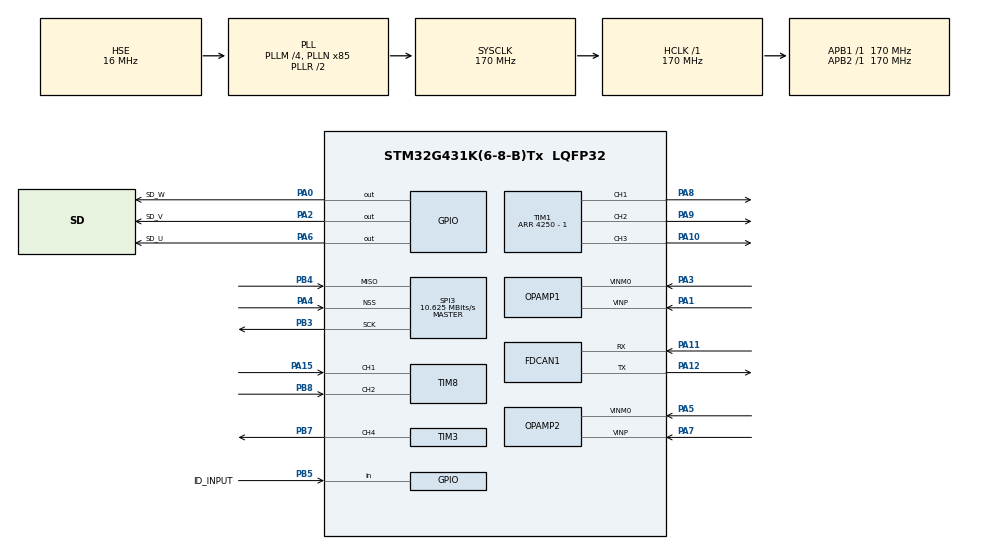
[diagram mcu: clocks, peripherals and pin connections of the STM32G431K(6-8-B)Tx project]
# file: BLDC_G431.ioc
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ADC1.Channel-0\#ChannelRegularConversion=ADC_CHANNEL_VOPAMP1
ADC1.DMAAccessModeView=ENABLE
ADC1.DMAContinuousRequests=ENABLE
ADC1.ExternalTrigConv=ADC_EXTERNALTRIG_T1_TRGO
ADC1.Mode=ADC_DUALMODE_REGSIMULT
ADC1.NbrOfConversion=1
ADC1.NbrOfConversionFlag=1
ADC1.SamplingTime-0\#ChannelRegularConversion=ADC_SAMPLETIME_12CYCLES_5
ADC1.TwoSamplingDelay=ADC_TWOSAMPLINGDELAY_1CYCLE
ADC1.master=1
ADC2.Channel-0\#ChannelRegularConversion=ADC_CHANNEL_VOPAMP2
ADC2.DMAAccessModeView=ENABLE
ADC2.Mode=ADC_DUALMODE_REGSIMULT
ADC2.NbrOfConversionFlag=1
ADC2.OffsetNumber-0\#ChannelRegularConversion=ADC_OFFSET_NONE
ADC2.Rank-0\#ChannelRegularConversion=1
ADC2.SamplingTime-0\#ChannelRegularConversion=ADC_SAMPLETIME_12CYCLES_5
Dma.ADC1.1.Direction=DMA_PERIPH_TO_MEMORY
Dma.ADC1.1.EventEnable=DISABLE
Dma.ADC1.1.Instance=DMA1_Channel1
Dma.ADC1.1.MemDataAlignment=DMA_MDATAALIGN_WORD
Dma.ADC1.1.MemInc=DMA_MINC_ENABLE
Dma.ADC1.1.Mode=DMA_CIRCULAR
Dma.ADC1.1.PeriphDataAlignment=DMA_PDATAALIGN_WORD
Dma.ADC1.1.PeriphInc=DMA_PINC_DISABLE
Dma.ADC1.1.Polarity=HAL_DMAMUX_REQ_GEN_RISING
Dma.ADC1.1.Priority=DMA_PRIORITY_VERY_HIGH
Dma.ADC1.1.RequestNumber=1
Dma.ADC1.1.SignalID=NONE
Dma.ADC1.1.SyncEnable=DISABLE
Dma.ADC1.1.SyncPolarity=HAL_DMAMUX_SYNC_NO_EVENT
Dma.ADC1.1.SyncRequestNumber=1
Dma.ADC1.1.SyncSignalID=NONE
Dma.Request0=TIM3_CH4
Dma.Request1=ADC1
Dma.TIM3_CH4.0.Direction=DMA_MEMORY_TO_PERIPH
Dma.TIM3_CH4.0.EventEnable=DISABLE
Dma.TIM3_CH4.0.Instance=DMA1_Channel2
Dma.TIM3_CH4.0.MemDataAlignment=DMA_MDATAALIGN_WORD
Dma.TIM3_CH4.0.MemInc=DMA_MINC_ENABLE
Dma.TIM3_CH4.0.Mode=DMA_CIRCULAR
Dma.TIM3_CH4.0.PeriphDataAlignment=DMA_PDATAALIGN_HALFWORD
Dma.TIM3_CH4.0.PeriphInc=DMA_PINC_DISABLE
Dma.TIM3_CH4.0.Polarity=HAL_DMAMUX_REQ_GEN_RISING
Dma.TIM3_CH4.0.Priority=DMA_PRIORITY_MEDIUM
Dma.TIM3_CH4.0.RequestNumber=1
Dma.TIM3_CH4.0.SignalID=NONE
Dma.TIM3_CH4.0.SyncEnable=DISABLE
Dma.TIM3_CH4.0.SyncPolarity=HAL_DMAMUX_SYNC_NO_EVENT
Dma.TIM3_CH4.0.SyncRequestNumber=1
Dma.TIM3_CH4.0.SyncSignalID=NONE
FDCAN1.AutoRetransmission=ENABLE
FDCAN1.CalculateBaudRateNominal=999999
FDCAN1.CalculateTimeBitNominal=1000
FDCAN1.CalculateTimeQuantumNominal=11.764705882352942
FDCAN1.DataPrescaler=5
FDCAN1.DataSyncJumpWidth=8
FDCAN1.DataTimeSeg1=8
FDCAN1.DataTimeSeg2=8
FDCAN1.FrameFormat=FDCAN_FRAME_FD_BRS
FDCAN1.NominalPrescaler=2
FDCAN1.NominalSyncJumpWidth=21
FDCAN1.NominalTimeSeg1=63
FDCAN1.NominalTimeSeg2=21
FDCAN1.StdFiltersNbr=1
Mcu.Family=STM32G4
Mcu.Name=STM32G431K(6-8-B)Tx
Mcu.Package=LQFP32
NVIC.ADC1_2_IRQn=true\:0\:0\:false\:false\:true\:true\:true\:true
NVIC.DMA1_Channel1_IRQn=true\:0\:0\:false\:false\:true\:false\:true\:true
NVIC.DMA1_Channel2_IRQn=true\:0\:0\:false\:false\:true\:false\:true\:true
NVIC.FDCAN1_IT0_IRQn=true\:0\:0\:false\:false\:true\:true\:true\:true
NVIC.PriorityGroup=NVIC_PRIORITYGROUP_4
NVIC.TIM1_UP_TIM16_IRQn=true\:0\:0\:false\:false\:true\:true\:true\:true
NVIC.TIM6_DAC_IRQn=true\:0\:0\:false\:false\:true\:true\:true\:true
NVIC.TIM8_UP_IRQn=true\:0\:0\:false\:false\:true\:true\:true\:true
OPAMP1.PgaGain=OPAMP_PGA_GAIN_32_OR_MINUS_31
OPAMP2.PgaGain=OPAMP_PGA_GAIN_32_OR_MINUS_31
PA0.GPIO_Label=SD_W
PA0.GPIO_PuPd=GPIO_PULLDOWN
PA0.Signal=GPIO_Output
PA1.Mode=PGA Internally connected_IO0_BIAS
PA1.Signal=OPAMP1_VINP
PA10.Signal=S_TIM1_CH3
PA11.Mode=FDCAN_Activate
PA11.Signal=FDCAN1_RX
PA12.Mode=FDCAN_Activate
PA12.Signal=FDCAN1_TX
PA13.Mode=Serial_Wire
PA13.Signal=SYS_JTMS-SWDIO
PA14.Mode=Serial_Wire
PA14.Signal=SYS_JTCK-SWCLK
PA15.Signal=S_TIM8_CH1
PA2.GPIO_Label=SD_V
PA2.GPIO_PuPd=GPIO_PULLDOWN
PA2.Signal=GPIO_Output
PA3.Mode=PGA Internally connected_IO0_BIAS
PA3.Signal=OPAMP1_VINM0
PA4.Mode=NSS_Signal_Hard_Input
PA4.Signal=SPI3_NSS
PA5.Mode=PGA Internally connected_IO0_BIAS
PA5.Signal=OPAMP2_VINM0
PA6.GPIO_Label=SD_U
PA6.GPIO_PuPd=GPIO_PULLDOWN
PA6.Signal=GPIO_Output
PA7.Mode=PGA Internally connected_IO0_BIAS
PA7.Signal=OPAMP2_VINP
PA8.Signal=S_TIM1_CH1
PA9.Signal=S_TIM1_CH2
PB3.Mode=RX_Only_Simplex_Unidirect_Master
PB3.Signal=SPI3_SCK
PB4.Mode=RX_Only_Simplex_Unidirect_Master
PB4.Signal=SPI3_MISO
PB5.GPIO_Label=ID_INPUT
PB5.Signal=GPIO_Input
PB7.GPIO_Speed=GPIO_SPEED_FREQ_HIGH
PB7.Signal=S_TIM3_CH4
PB8-BOOT0.Signal=S_TIM8_CH2
PF0-OSC_IN.Mode=HSE-External-Oscillator
PF0-OSC_IN.Signal=RCC_OSC_IN
PF1-OSC_OUT.Mode=HSE-External-Oscillator
PF1-OSC_OUT.Signal=RCC_OSC_OUT
ProjectManager.HeapSize=0x200
ProjectManager.StackSize=0x400
ProjectManager.TargetToolchain=CMake
RCC.ADC12Freq_Value=170000000
RCC.AHBFreq_Value=170000000
RCC.APB1Freq_Value=170000000
RCC.APB1TimFreq_Value=170000000
RCC.APB2Freq_Value=170000000
RCC.APB2TimFreq_Value=170000000
RCC.CortexFreq_Value=170000000
RCC.EXTERNAL_CLOCK_VALUE=12288000
RCC.EnbaleCSS=true
RCC.HCLKFreq_Value=170000000
RCC.HSE_VALUE=16000000
RCC.HSI48_VALUE=48000000
RCC.HSI_VALUE=16000000
RCC.LSE_VALUE=32768
RCC.PLLM=RCC_PLLM_DIV4
RCC.PLLN=85
RCC.PLLSourceVirtual=RCC_PLLSOURCE_HSE
RCC.SYSCLKFreq_VALUE=170000000
RCC.SYSCLKSource=RCC_SYSCLKSOURCE_PLLCLK
RCC.USBFreq_Value=170000000
RCC.VCOOutputFreq_Value=340000000
SH.S_TIM1_CH1.0=TIM1_CH1,PWM Generation1 CH1
SH.S_TIM1_CH2.0=TIM1_CH2,PWM Generation2 CH2
SH.S_TIM1_CH3.0=TIM1_CH3,PWM Generation3 CH3
SH.S_TIM3_CH4.0=TIM3_CH4,PWM Generation4 CH4
SH.S_TIM8_CH1.0=TIM8_CH1,Encoder_Interface
SH.S_TIM8_CH2.0=TIM8_CH2,Encoder_Interface
SPI3.BaudRatePrescaler=SPI_BAUDRATEPRESCALER_16
SPI3.CalculateBaudRate=10.625 MBits/s
SPI3.Direction=SPI_DIRECTION_2LINES_RXONLY
SPI3.Mode=SPI_MODE_MASTER
SPI3.VirtualNSS=VM_NSSHARD
SPI3.VirtualType=VM_MASTER
STMicroelectronics.X-CUBE-ALGOBUILD.1.5.0.LibraryCcDSPOoLibraryJjDSPOoLibrary=true
TIM1.BreakPolarity=TIM_BREAKPOLARITY_HIGH
TIM1.Channel-PWM\ Generation1\ CH1=TIM_CHANNEL_1
TIM1.Channel-PWM\ Generation2\ CH2=TIM_CHANNEL_2
TIM1.Channel-PWM\ Generation3\ CH3=TIM_CHANNEL_3
TIM1.CounterMode=TIM_COUNTERMODE_CENTERALIGNED1
TIM1.OCMode_PWM-PWM\ Generation1\ CH1=TIM_OCMODE_PWM2
TIM1.OCMode_PWM-PWM\ Generation2\ CH2=TIM_OCMODE_PWM2
TIM1.OCMode_PWM-PWM\ Generation3\ CH3=TIM_OCMODE_PWM2
TIM1.PeriodNoDither=4250 - 1
TIM1.RepetitionCounter=1
TIM1.TIM_MasterOutputTrigger=TIM_TRGO_UPDATE
TIM1.TIM_MasterOutputTrigger2=TIM_TRGO2_RESET
TIM3.Channel-PWM\ Generation4\ CH4=TIM_CHANNEL_4
TIM3.OCFastMode_PWM-PWM\ Generation4\ CH4=TIM_OCFAST_ENABLE
TIM3.PeriodNoDither=19
TIM3.Prescaler=9
TIM6.PeriodNoDither=999
TIM6.Prescaler=169
VP_ADC1_OPAMP_INTERNAL1.Mode=IN-OPAMP1
VP_ADC2_OPAMP_INTERNAL2.Mode=IN-OPAMP2
VP_CORDIC_VS_CORDIC.Mode=CORDIC_Activate
VP_STMicroelectronics.X-CUBE-ALGOBUILD_VS_DSPOoLibraryJjLibrary_1.5.0_1.5.0.Mode=DSPOoLibraryJjLibrary
VP_SYS_VS_DBSignals.Mode=DisableDeadBatterySignals
VP_TIM6_VS_ClockSourceINT.Mode=Enable_Timer
board=custom

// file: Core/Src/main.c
/* USER CODE BEGIN Header */
/**
  ******************************************************************************
  * @file           : main.c
  * @brief          : Main program body
  ******************************************************************************
  * @attention
  *
  * Copyright (c) 2026 STMicroelectronics.
  * All rights reserved.
  *
  * This software is licensed under terms that can be found in the LICENSE file
  * in the root directory of this software component.
  * If no LICENSE file comes with this software, it is provided AS-IS.
  *
  ******************************************************************************
  */
/* USER CODE END Header */
#include "main.h"
#include "adc.h"
#include "cordic.h"
#include "dma.h"
#include "fdcan.h"
#include "opamp.h"
#include "spi.h"
#include "tim.h"
#include "gpio.h"

/* USER CODE BEGIN Includes */
#include "main_app.hpp"
/* USER CODE END Includes */

void SystemClock_Config(void);

int main(void)
{

  /* MCU Configuration--------------------------------------------------------*/

  /* Reset of all peripherals, Initializes the Flash interface and the Systick. */
   HAL_Init();

  /* Configure the system clock */
  SystemClock_Config();

  /* Initialize all configured peripherals */
  MX_GPIO_Init();
  MX_DMA_Init();
  MX_FDCAN1_Init();
  MX_OPAMP1_Init();
  MX_OPAMP2_Init();
  MX_TIM1_Init();
  MX_ADC1_Init();
  MX_SPI3_Init();
  MX_TIM3_Init();
  MX_TIM8_Init();
  MX_CORDIC_Init();
  MX_TIM6_Init();
  MX_ADC2_Init();
  /* USER CODE BEGIN 2 */
  main_setup();
  /* USER CODE END 2 */

  /* Infinite loop */
  while (1)
  {
    /* USER CODE BEGIN 3 */
    HAL_Delay(100);
  }
  /* USER CODE END 3 */
}

void SystemClock_Config(void)
{
  RCC_OscInitTypeDef RCC_OscInitStruct = {0};
  RCC_ClkInitTypeDef RCC_ClkInitStruct = {0};

  /** Configure the main internal regulator output voltage
  */
  HAL_PWREx_ControlVoltageScaling(PWR_REGULATOR_VOLTAGE_SCALE1_BOOST);

  /** Initializes the RCC Oscillators according to the specified parameters
  * in the RCC_OscInitTypeDef structure.
  */
  RCC_OscInitStruct.OscillatorType = RCC_OSCILLATORTYPE_HSE;
  RCC_OscInitStruct.HSEState = RCC_HSE_ON;
  RCC_OscInitStruct.PLL.PLLState = RCC_PLL_ON;
  RCC_OscInitStruct.PLL.PLLSource = RCC_PLLSOURCE_HSE;
  RCC_OscInitStruct.PLL.PLLM = RCC_PLLM_DIV4;
  RCC_OscInitStruct.PLL.PLLN = 85;
  RCC_OscInitStruct.PLL.PLLP = RCC_PLLP_DIV2;
  RCC_OscInitStruct.PLL.PLLQ = RCC_PLLQ_DIV2;
  RCC_OscInitStruct.PLL.PLLR = RCC_PLLR_DIV2;
  if (HAL_RCC_OscConfig(&RCC_OscInitStruct) != HAL_OK)
  {
    Error_Handler();
  }

  /** Initializes the CPU, AHB and APB buses clocks
  */
  RCC_ClkInitStruct.ClockType = RCC_CLOCKTYPE_HCLK|RCC_CLOCKTYPE_SYSCLK
                              |RCC_CLOCKTYPE_PCLK1|RCC_CLOCKTYPE_PCLK2;
  RCC_ClkInitStruct.SYSCLKSource = RCC_SYSCLKSOURCE_PLLCLK;
  RCC_ClkInitStruct.AHBCLKDivider = RCC_SYSCLK_DIV1;
  RCC_ClkInitStruct.APB1CLKDivider = RCC_HCLK_DIV1;
  RCC_ClkInitStruct.APB2CLKDivider = RCC_HCLK_DIV1;

  if (HAL_RCC_ClockConfig(&RCC_ClkInitStruct, FLASH_LATENCY_4) != HAL_OK)
  {
    Error_Handler();
  }

  /** Enables the Clock Security System
  */
  HAL_RCC_EnableCSS();
}

void Error_Handler(void)
{
  __disable_irq();
  while (1)
  {
  }
}
